# MKL28Z7 register map
Vendor: Freescale Semiconductor, Inc.; Series: Kinetis_L; File version: 1.6
CPU: CM0PLUS r0p0, little endian, no MPU, no FPU, VTOR, 2 interrupt priority bits
Registers are 32-bit, read-write, reset 0x0 unless marked. A register's access mark holds for its fields unless they carry their own. Offsets are from the block's base; [hi:lo] are bit positions; {n}, {i} and the like mark numbered series; 'fields as' and 'values as' point back to an identical list.

## MTB0_ROM — System ROM
Base 0xF0002000; register names take the prefix MTB0_ROM_
{0x0+4i} ENTRY{i} (i=0..3) ro reset not defined
  [31:0] ENTRY
0x10 TABLEMARK ro — End of Table Marker Register
  [31:0] MARK
0xFCC SYSACCESS ro reset 0x1 — System Access Register
0xFD0 PERIPHID{x} (x=4,5,6,7,0,1,2,3; step 0x4) ro reset not defined — Peripheral ID Register
  [31:0] PERIPHID
{0xFF0+4i} COMPID{i} (i=0..3) ro reset not defined — Component ID Register
  [31:0] COMPID — Component ID

## MCM0 — Core Platform Miscellaneous Control Module
Base 0xF0003000; register names take the prefix MCM0_
0x08 PLASC 16-bit ro reset 0xF — Crossbar Switch (AXBS) Slave Configuration
  [7:0] ASC — Each bit in the ASC field indicates whether there is a corresponding connection to the crossbar switch's slave input port.
    0=A bus slave connection to AXBS input port n is absent; 1=A bus slave connection to AXBS input port n is present
0x0A PLAMC 16-bit ro reset 0xF — Crossbar Switch (AXBS) Master Configuration
  [7:0] AMC — Each bit in the AMC field indicates whether there is a corresponding connection to the AXBS master input port.
    0=A bus master connection to AXBS input port n is absent; 1=A bus master connection to AXBS input port n is present
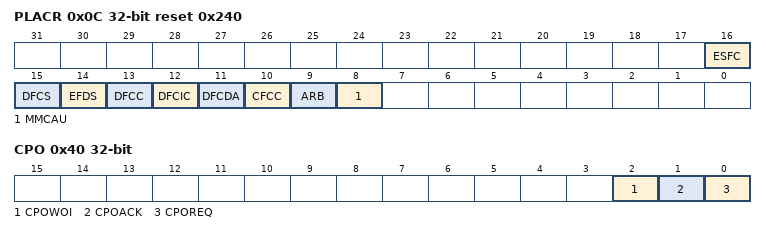
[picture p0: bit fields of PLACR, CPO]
0x0C PLACR reset 0x240 — Platform Control Register
  [16] ESFC — Enable Stalling Flash Controller
    0=Disable stalling flash controller when flash is busy; 1=Enable stalling flash controller when flash is busy
  [15] DFCS — Disable Flash Controller Speculation
    0=Enable flash controller speculation; 1=Disable flash controller speculation
  [14] EFDS — Enable Flash Data Speculation
    0=Disable flash data speculation; 1=Enable flash data speculation
  [13] DFCC — Disable Flash Controller Cache
    0=Enable flash controller cache; 1=Disable flash controller cache
  [12] DFCIC — Disable Flash Controller Instruction Caching
    0=Enable flash controller instruction caching; 1=Disable flash controller instruction caching
  [11] DFCDA — Disable Flash Controller Data Caching
    0=Enable flash controller data caching; 1=Disable flash controller data caching
  [10] CFCC wo — Clear Flash Controller Cache
  [9] ARB — Arbitration select
    0=Fixed-priority arbitration for the crossbar masters; 1=Round-robin arbitration for the crossbar masters
  [8] MMCAU ro — MMCAU Present
    0=MMCAU is disabled; 1=MMCAU is enabled
0x40 CPO — Compute Operation Control Register
  [2] CPOWOI — Compute Operation Wake-up on Interrupt
    0=No effect; 1=When set, the CPOREQ is cleared on any interrupt or exception vector fetch
  [1] CPOACK ro — Compute Operation Acknowledge
    0=Compute operation entry has not completed or compute operation exit has completed; 1=Compute operation entry has completed or compute operation exit has not completed
  [0] CPOREQ — Compute Operation Request
    0=Request is cleared; 1=Request Compute Operation

## MMDVSQ0 — Divide and Square Root
Base 0xF0004000; register names take the prefix MMDVSQ0_
0x00 DEND reset not defined — Dividend Register
  [31:0] DIVIDEND
0x04 DSOR reset not defined — Divisor Register
  [31:0] DIVISOR
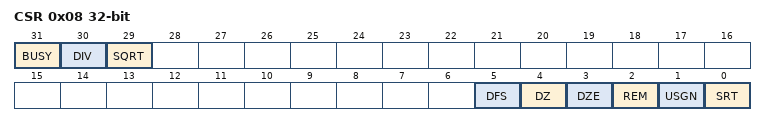
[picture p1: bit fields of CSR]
0x08 CSR (reset mask 0x9FFFFFFF) — Control/Status Register
  [31] BUSY ro
    0=MMDVSQ is idle; 1=MMDVSQ is busy performing a divide or square root calculation
  [30] DIV ro — DIVIDE
    0=Current or last MMDVSQ operation was not a divide; 1=Current or last MMDVSQ operation was a divide
  [29] SQRT ro — SQUARE ROOT
    0=Current or last MMDVSQ operation was not a square root; 1=Current or last MMDVSQ operation was a square root
  [5] DFS — Disable Fast Start
    0=A divide operation is initiated by a write to the DSOR register; 1=A divide operation is initiated by a write to the CSR register with CSR[SRT] = 1
  [4] DZ ro — Divide-by-Zero
    0=The last divide operation had a non-zero divisor, that is, DSOR != 0; 1=The last divide operation had a zero divisor, that is, DSOR = 0
  [3] DZE — Divide-by-Zero-Enable
    0=Reads of the RES register return the register contents; 1=If CSR[DZ] = 1, an attempted read of RES register is error terminated to signal a divide-by-zero, else the register contents are returned
  [2] REM — REMainder calculation
    0=Return the quotient in the RES for the divide calculation; 1=Return the remainder in the RES for the divide calculation
  [1] USGN — Unsigned calculation
    0=Perform a signed divide; 1=Perform an unsigned divide
  [0] SRT wo — Start
    0=No operation initiated; 1=If CSR[DFS] = 1, then initiate a divide calculation, else ignore
0x0C RES reset not defined — Result Register
  [31:0] RESULT
0x10 RCND reset not defined — Radicand Register
  [31:0] RADICAND

## CAU0 — Memory Mapped Cryptographic Acceleration Unit (MMCAU)
Base 0xF0005000
{0x0+4i} CAU_DIRECT{i} wo (i=0..15) — Direct access register {i}
  [31:0] CAU_DIRECT{i} — Direct register {i}
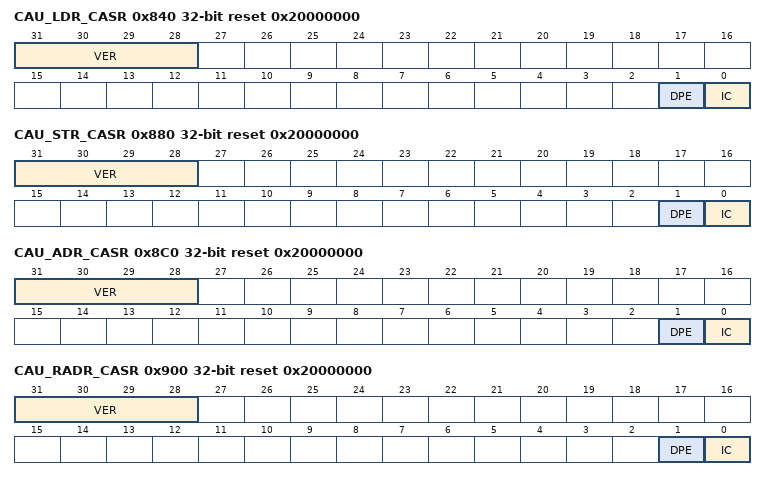
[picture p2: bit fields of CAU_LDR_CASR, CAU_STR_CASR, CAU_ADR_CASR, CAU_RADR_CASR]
0x840 CAU_LDR_CASR wo reset 0x20000000 — Status register - Load Register command
  [31:28] VER — CAU version
    1=Initial CAU version; 2=Second version, added support for SHA-256 algorithm.(This is the value on this device)
  [1] DPE
    0=No error detected; 1=DES key parity error detected
  [0] IC
    0=No illegal commands issued; 1=Illegal command issued
0x844 CAU_LDR_CAA wo — Accumulator register - Load Register command
  [31:0] ACC
{0x848+4i} CAU_LDR_CA{i} wo (i=0..8) — General Purpose Register {i} - Load Register command
0x880 CAU_STR_CASR ro reset 0x20000000 — Status register - Store Register command
  fields as CAU_LDR_CASR
0x884 CAU_STR_CAA ro — Accumulator register - Store Register command
  [31:0] ACC
{0x888+4i} CAU_STR_CA{i} ro (i=0..8) — General Purpose Register {i} - Store Register command
0x8C0 CAU_ADR_CASR wo reset 0x20000000 — Status register - Add Register command
  fields as CAU_LDR_CASR
0x8C4 CAU_ADR_CAA wo — Accumulator register - Add to register command
  [31:0] ACC
{0x8C8+4i} CAU_ADR_CA{i} wo (i=0..8) — General Purpose Register {i} - Add to register command
0x900 CAU_RADR_CASR wo reset 0x20000000 — Status register - Reverse and Add to Register command
  fields as CAU_LDR_CASR
0x904 CAU_RADR_CAA wo — Accumulator register - Reverse and Add to Register command
  [31:0] ACC
{0x908+4i} CAU_RADR_CA{i} wo (i=0..8) — General Purpose Register {i} - Reverse and Add to Register command
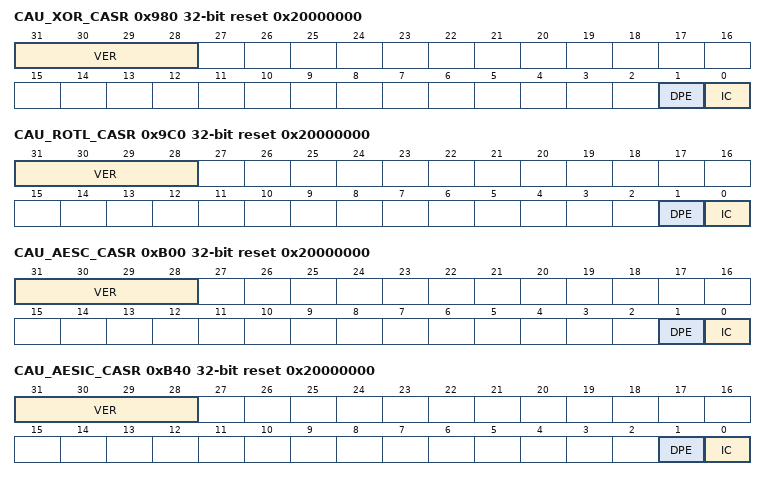
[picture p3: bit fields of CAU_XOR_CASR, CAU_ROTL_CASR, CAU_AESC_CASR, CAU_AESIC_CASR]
0x980 CAU_XOR_CASR wo reset 0x20000000 — Status register - Exclusive Or command
  fields as CAU_LDR_CASR
0x984 CAU_XOR_CAA wo — Accumulator register - Exclusive Or command
  [31:0] ACC
{0x988+4i} CAU_XOR_CA{i} wo (i=0..8) — General Purpose Register {i} - Exclusive Or command
0x9C0 CAU_ROTL_CASR wo reset 0x20000000 — Status register - Rotate Left command
  fields as CAU_LDR_CASR
0x9C4 CAU_ROTL_CAA wo — Accumulator register - Rotate Left command
  [31:0] ACC
{0x9C8+4i} CAU_ROTL_CA{i} wo (i=0..8) — General Purpose Register {i} - Rotate Left command
0xB00 CAU_AESC_CASR wo reset 0x20000000 — Status register - AES Column Operation command
  fields as CAU_LDR_CASR
0xB04 CAU_AESC_CAA wo — Accumulator register - AES Column Operation command
  [31:0] ACC
{0xB08+4i} CAU_AESC_CA{i} wo (i=0..8) — General Purpose Register {i} - AES Column Operation command
0xB40 CAU_AESIC_CASR wo reset 0x20000000 — Status register - AES Inverse Column Operation command
  fields as CAU_LDR_CASR
0xB44 CAU_AESIC_CAA wo — Accumulator register - AES Inverse Column Operation command
  [31:0] ACC
{0xB48+4i} CAU_AESIC_CA{i} wo (i=0..8) — General Purpose Register {i} - AES Inverse Column Operation command
